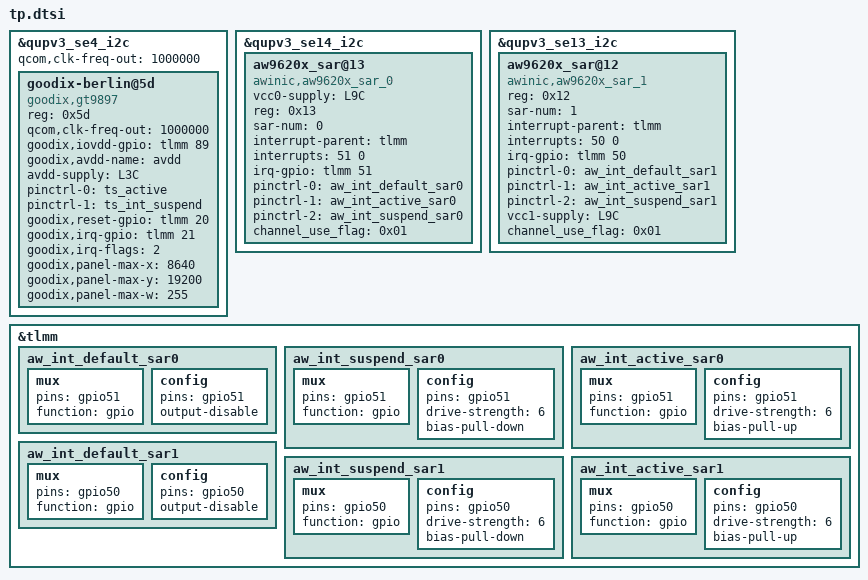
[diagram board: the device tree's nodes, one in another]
&qupv3_se4_i2c {
	#address-cells = <1>;
	#size-cells = <0>;

	status = "ok";
	qcom,clk-freq-out = <1000000>;
	goodix-berlin@5d {
			compatible = "goodix,gt9897";
			reg = <0x5d>;
			status = "ok";
			qcom,clk-freq-out = <1000000>;
			//vdd-supply = <&L3C>;
			//goodix,avdd-gpio = <&tlmm 90 0x00>;
			goodix,iovdd-gpio =<&tlmm 89 0x00>;
			goodix,avdd-name = "avdd";
			avdd-supply = <&L3C>;
			//goodix,iovdd-name = "iovdd";
			//iovdd-supply = <&tlmm 83 0x0>;
			pinctrl-names = "pmx_ts_active","pmx_ts_suspend";
			pinctrl-0 = <&ts_active>;
			pinctrl-1 = <&ts_int_suspend>;
			goodix,reset-gpio = <&tlmm 20 0x0>;
			goodix,irq-gpio = <&tlmm 21 0x2800>;
			goodix,irq-flags = <2>; 
			goodix,panel-max-x = <8640>;
			goodix,panel-max-y = <19200>;
			goodix,panel-max-w = <255>;
	};
};
&qupv3_se14_i2c {
	    status = "ok";
		aw9620x_sar@13 {
			compatible = "awinic,aw9620x_sar_0";
			vcc0-supply = <&L9C>;
			reg = <0x13>;
			sar-num = < 0 >;
			interrupt-parent = < &tlmm >;
			interrupts = <51 0>;
			irq-gpio = <&tlmm 51 0>;
			pinctrl-names = "aw_int_default_sar0", "aw_int_active_sar0", "aw_int_suspend_sar0";
			pinctrl-0 = <&aw_int_default_sar0>;
			pinctrl-1 = <&aw_int_active_sar0>;
			pinctrl-2 = <&aw_int_suspend_sar0>;
			channel_use_flag = <0x01>;
			status = "okay";
		};
};
&qupv3_se13_i2c {
		status = "ok";
		aw9620x_sar@12 {
			compatible = "awinic,aw9620x_sar_1";
			reg = < 0x12 >;
			sar-num = < 1 >;
			interrupt-parent = < &tlmm >;
			interrupts = <50 0>;
			irq-gpio = <&tlmm 50 0>;
			pinctrl-names = "aw_int_default_sar1", "aw_int_active_sar1", "aw_int_suspend_sar1";
			pinctrl-0 = <&aw_int_default_sar1>;
			pinctrl-1 = <&aw_int_active_sar1>;
			pinctrl-2 = <&aw_int_suspend_sar1>;
			vcc1-supply = <&L9C>;
			channel_use_flag = <0x01>;
			status = "okay";
		};
};
&tlmm {
	
		aw_int_default_sar0: aw_int_default_sar0 {

			mux {
				pins = "gpio51";
				function = "gpio";
			};
			config {
				pins = "gpio51";
				output-disable;
			};
		};
		aw_int_suspend_sar0: aw_int_suspend_sar0 {
		   mux {
			   pins = "gpio51";
			   function = "gpio";
		   };
		 config {
			  pins = "gpio51";
			  drive-strength = <6>;
			  bias-pull-down;
		   };
		};
		aw_int_active_sar0: aw_int_active_sar0 {
		  mux {
			  pins = "gpio51";
			  function = "gpio";
		   };
		   config {
			 pins = "gpio51";
			 drive-strength = <6>;
			 bias-pull-up;
		   };
		};
	aw_int_default_sar1: aw_int_default_sar1 {

       mux {
           pins = "gpio50";
           function = "gpio";
       };
      config {
           pins = "gpio50";
           output-disable;
       };
    };
    aw_int_suspend_sar1: aw_int_suspend_sar1 {
       mux {
           pins = "gpio50";
           function = "gpio";
       };
     config {
          pins = "gpio50";
          drive-strength = <6>;
          bias-pull-down;
       };
    };
    aw_int_active_sar1: aw_int_active_sar1 {
      mux {
          pins = "gpio50";
          function = "gpio";
       };
    config {
         pins = "gpio50";
         drive-strength = <6>;
         bias-pull-up;
       };
    };

};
